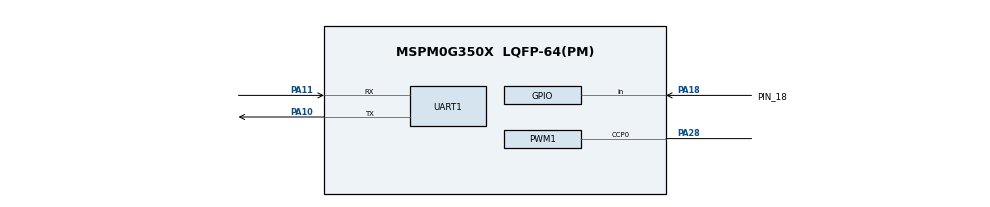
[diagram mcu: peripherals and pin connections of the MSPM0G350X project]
/**
 * These arguments were used when this file was generated. They will be automatically applied on subsequent loads
 * via the GUI or CLI. Run CLI with '--help' for additional information on how to override these arguments.
 * @cliArgs --device "MSPM0G350X" --package "LQFP-64(PM)" --part "Default" --product "mspm0_sdk@2.01.00.03"
 * @versions {"tool":"1.20.0+3587"}
 */

/**
 * Import the modules used in this configuration.
 */
const GPIO    = scripting.addModule("/ti/driverlib/GPIO", {}, false);
const GPIO1   = GPIO.addInstance();
const PWM     = scripting.addModule("/ti/driverlib/PWM", {}, false);
const PWM1    = PWM.addInstance();
const SYSCTL  = scripting.addModule("/ti/driverlib/SYSCTL");
const SYSTICK = scripting.addModule("/ti/driverlib/SYSTICK");
const UART    = scripting.addModule("/ti/driverlib/UART", {}, false);
const UART1   = UART.addInstance();

/**
 * Write custom configuration values to the imported modules.
 */
const gate7  = system.clockTree["MFCLKGATE"];
gate7.enable = true;

GPIO1.$name                              = "KEY";
GPIO1.port                               = "PORTA";
GPIO1.associatedPins[0].$name            = "PIN_18";
GPIO1.associatedPins[0].direction        = "INPUT";
GPIO1.associatedPins[0].assignedPin      = "18";
GPIO1.associatedPins[0].internalResistor = "PULL_DOWN";
GPIO1.associatedPins[0].interruptEn      = true;
GPIO1.associatedPins[0].polarity         = "RISE";
GPIO1.associatedPins[0].pin.$assign      = "PA18";

const Board = scripting.addModule("/ti/driverlib/Board", {}, false);

PWM1.ccIndex                            = [0];
PWM1.timerCount                         = 20000;
PWM1.timerStartTimer                    = true;
PWM1.clockPrescale                      = 32;
PWM1.pwmMode                            = "EDGE_ALIGN_UP";
PWM1.$name                              = "PWM_SERVO";
PWM1.peripheral.ccp0Pin.$assign         = "PA28";
PWM1.PWM_CHANNEL_0.$name                = "ti_driverlib_pwm_PWMTimerCC1";
PWM1.ccp0PinConfig.direction            = scripting.forceWrite("OUTPUT");
PWM1.ccp0PinConfig.hideOutputInversion  = scripting.forceWrite(false);
PWM1.ccp0PinConfig.onlyInternalResistor = scripting.forceWrite(false);
PWM1.ccp0PinConfig.passedPeripheralType = scripting.forceWrite("Digital");
PWM1.ccp0PinConfig.$name                = "ti_driverlib_gpio_GPIOPinGeneric3";

SYSCTL.forceDefaultClkConfig = true;
SYSCTL.clockTreeEn           = true;

SYSTICK.periodEnable      = true;
SYSTICK.period            = 32000;
SYSTICK.systickEnable     = true;
SYSTICK.interruptPriority = "0";

UART1.$name                    = "UART_0";
UART1.uartClkSrc               = "MFCLK";
UART1.enabledInterrupts        = ["RX"];
UART1.peripheral.$assign       = "UART0";
UART1.peripheral.rxPin.$assign = "PA11";
UART1.peripheral.txPin.$assign = "PA10";
UART1.txPinConfig.$name        = "ti_driverlib_gpio_GPIOPinGeneric0";
UART1.rxPinConfig.$name        = "ti_driverlib_gpio_GPIOPinGeneric1";

/**
 * Pinmux solution for unlocked pins/peripherals. This ensures that minor changes to the automatic solver in a future
 * version of the tool will not impact the pinmux you originally saw.  These lines can be completely deleted in order to
 * re-solve from scratch.
 */
Board.peripheral.$suggestSolution          = "DEBUGSS";
Board.peripheral.swclkPin.$suggestSolution = "PA20";
Board.peripheral.swdioPin.$suggestSolution = "PA19";
PWM1.peripheral.$suggestSolution           = "TIMA1";
